# MKW40Z4 register map
Vendor: Freescale Semiconductor, Inc.; Series: Kinetis_W; File version: 1.6
CPU: CM0PLUS r0p0, little endian, no MPU, no FPU, VTOR, 2 interrupt priority bits
Registers are 32-bit, read-write, reset 0x0 unless marked. A register's access mark holds for its fields unless they carry their own. Offsets are from the block's base; [hi:lo] are bit positions; {n}, {i} and the like mark numbered series; 'fields as' and 'values as' point back to an identical list.

## PORTB — Pin Control and Interrupts
Base 0x4004A000; register names take the prefix PORTB_
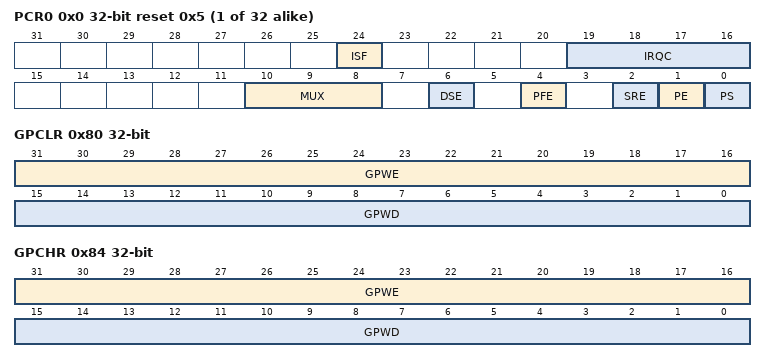
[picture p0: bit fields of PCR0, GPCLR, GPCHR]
{0x0+4i} PCR{i} (i=0..31) reset 0x5 — Pin Control Register n
  [24] ISF — Interrupt Status Flag
    0=Configured interrupt is not detected; 1=Configured interrupt is detected. If the pin is configured to generate a DMA request, then the corresponding flag will be cleared automatically at the completion of the requested DMA transfer. Otherwise, the flag remains set until a logic 1 is written to the flag. If the pin is configured for a level sensitive interrupt and the pin remains asserted, then the flag is set again immediately after it is cleared.
  [19:16] IRQC — Interrupt Configuration
    0=Interrupt Status Flag (ISF) is disabled; 1=ISF flag and DMA request on rising edge; 2=ISF flag and DMA request on falling edge; 3=ISF flag and DMA request on either edge; 8=ISF flag and Interrupt when logic 0; 9=ISF flag and Interrupt on rising-edge; 10=ISF flag and Interrupt on falling-edge; 11=ISF flag and Interrupt on either edge; 12=ISF flag and Interrupt when logic 1
  [10:8] MUX — Pin Mux Control
    0=Pin disabled (analog); 1=Alternative 1 (GPIO); {v}=Alternative {v} (chip-specific) (v=2..7)
  [6] DSE — Drive Strength Enable
    0=Low drive strength is configured on the corresponding pin, if pin is configured as a digital output; 1=High drive strength is configured on the corresponding pin, if pin is configured as a digital output
  [4] PFE — Passive Filter Enable
    0=Passive input filter is disabled on the corresponding pin; 1=Passive input filter is enabled on the corresponding pin, if the pin is configured as a digital input. Refer to the device data sheet for filter characteristics.
  [2] SRE — Slew Rate Enable
    0=Fast slew rate is configured on the corresponding pin, if the pin is configured as a digital output; 1=Slow slew rate is configured on the corresponding pin, if the pin is configured as a digital output
  [1] PE — Pull Enable
    0=Internal pullup or pulldown resistor is not enabled on the corresponding pin; 1=Internal pullup or pulldown resistor is enabled on the corresponding pin, if the pin is configured as a digital input
  [0] PS — Pull Select
    0=Internal pulldown resistor is enabled on the corresponding pin, if the corresponding PE field is set; 1=Internal pullup resistor is enabled on the corresponding pin, if the corresponding PE field is set
0x80 GPCLR wo — Global Pin Control Low Register
  [31:16] GPWE — Global Pin Write Enable
    0=Corresponding Pin Control Register is not updated with the value in GPWD; 1=Corresponding Pin Control Register is updated with the value in GPWD
  [15:0] GPWD — Global Pin Write Data
0x84 GPCHR wo — Global Pin Control High Register
  fields as GPCLR
0xA0 ISFR — Interrupt Status Flag Register
  [31:0] ISF — Interrupt Status Flag
    values as PCR0.ISF

## PORTC — Pin Control and Interrupts
Base 0x4004B000; register names take the prefix PORTC_
Registers as PORTB.

## RSIM — Radio System Integration Module
Base 0x40059000; register names take the prefix RSIM_
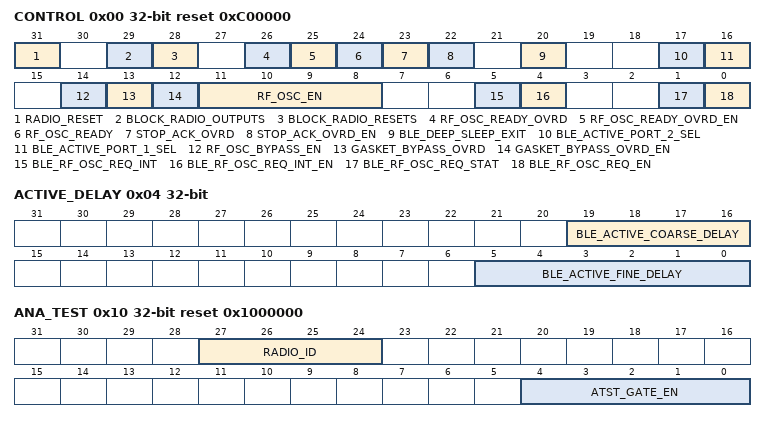
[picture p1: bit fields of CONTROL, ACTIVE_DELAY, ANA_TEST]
0x00 CONTROL reset 0xC00000 — RSIM Control
  [31] RADIO_RESET — Software Reset for the Radio
  [29] BLOCK_RADIO_OUTPUTS
  [28] BLOCK_RADIO_RESETS
  [26] RF_OSC_READY_OVRD — RF Ref Osc Ready Override
  [25] RF_OSC_READY_OVRD_EN — RF Ref Osc Ready Override Enable
  [24] RF_OSC_READY ro — RF Ref Osc Ready
  [23] STOP_ACK_OVRD — Stop Acknowledge Override
  [22] STOP_ACK_OVRD_EN — Stop Acknowledge Override Enable
  [20] BLE_DEEP_SLEEP_EXIT
  [17] BLE_ACTIVE_PORT_2_SEL — BLE Active port 2 select
  [16] BLE_ACTIVE_PORT_1_SEL — BLE Active port 1 select
  [14] RF_OSC_BYPASS_EN — RF Ref Osc Bypass Enable
  [13] GASKET_BYPASS_OVRD — Gasket Bypass Override
  [12] GASKET_BYPASS_OVRD_EN — Gasket Bypass Override Enable
  [11:8] RF_OSC_EN — RF Ref Osc Enable [3:0]
    0=RF Ref Osc will be controlled by the SoC or the BLE link layer; 1=RF Ref Osc on in Run/Wait; 3=RF Ref Osc on in Stop; 7=RF Ref Osc on in VLPR/VLPW; 15=RF Ref Osc on in VLPS
  [5] BLE_RF_OSC_REQ_INT — BLE Ref Osc (Sysclk) Request Interrupt Flag
  [4] BLE_RF_OSC_REQ_INT_EN — BLE Ref Osc (Sysclk) Request Interrupt Enable
  [1] BLE_RF_OSC_REQ_STAT ro — BLE Ref Osc (Sysclk) Request Status
  [0] BLE_RF_OSC_REQ_EN — BLE Ref Osc (Sysclk) Request Enable
0x04 ACTIVE_DELAY — RSIM BLE Active Delay
  [19:16] BLE_ACTIVE_COARSE_DELAY — The SoC Flash is presented with a BLE Active early warning signal to allow the Flash to complete any program or erase activities prior to a Radio communication event
  [5:0] BLE_ACTIVE_FINE_DELAY — The SoC Flash is presented with a BLE Active early warning signal to allow the Flash to complete any program or erase activities prior to a Radio communication event
0x08 MAC_MSB ro — RSIM MAC MSB
  [7:0] MAC_ADDR_MSB — MAC Address MSB
0x0C MAC_LSB ro — RSIM MAC LSB
  [31:0] MAC_ADDR_LSB — MAC Address LSB
0x10 ANA_TEST reset 0x1000000 — RSIM Analog Test
  [27:24] RADIO_ID ro — Radio Version ID number
    1=Apache 1.0; 2=Apache 2.0; 3=2.4 GHz Radio 2.0, Used by various SoC implementations
  [4:0] ATST_GATE_EN — ATST Transmission Gate Enables

## Notices in the file
Redistribution and use in source and binary forms, with or without modification,
are permitted provided that the following conditions are met:
o Redistributions of source code must retain the above copyright notice, this list
of conditions and the following disclaimer.
o Redistributions in binary form must reproduce the above copyright notice, this
list of conditions and the following disclaimer in the documentation and/or
other materials provided with the distribution.
o Neither the name of Freescale Semiconductor, Inc. nor the names of its
contributors may be used to endorse or promote products derived from this
software without specific prior written permission.
THIS SOFTWARE IS PROVIDED BY THE COPYRIGHT HOLDERS AND CONTRIBUTORS "AS IS" AND
ANY EXPRESS OR IMPLIED WARRANTIES, INCLUDING, BUT NOT LIMITED TO, THE IMPLIED
WARRANTIES OF MERCHANTABILITY AND FITNESS FOR A PARTICULAR PURPOSE ARE
DISCLAIMED. IN NO EVENT SHALL THE COPYRIGHT HOLDER OR CONTRIBUTORS BE LIABLE FOR
ANY DIRECT, INDIRECT, INCIDENTAL, SPECIAL, EXEMPLARY, OR CONSEQUENTIAL DAMAGES
(INCLUDING, BUT NOT LIMITED TO, PROCUREMENT OF SUBSTITUTE GOODS OR SERVICES;
LOSS OF USE, DATA, OR PROFITS; OR BUSINESS INTERRUPTION) HOWEVER CAUSED AND ON
ANY THEORY OF LIABILITY, WHETHER IN CONTRACT, STRICT LIABILITY, OR TORT
(INCLUDING NEGLIGENCE OR OTHERWISE) ARISING IN ANY WAY OUT OF THE USE OF THIS
SOFTWARE, EVEN IF ADVISED OF THE POSSIBILITY OF SUCH DAMAGE.
